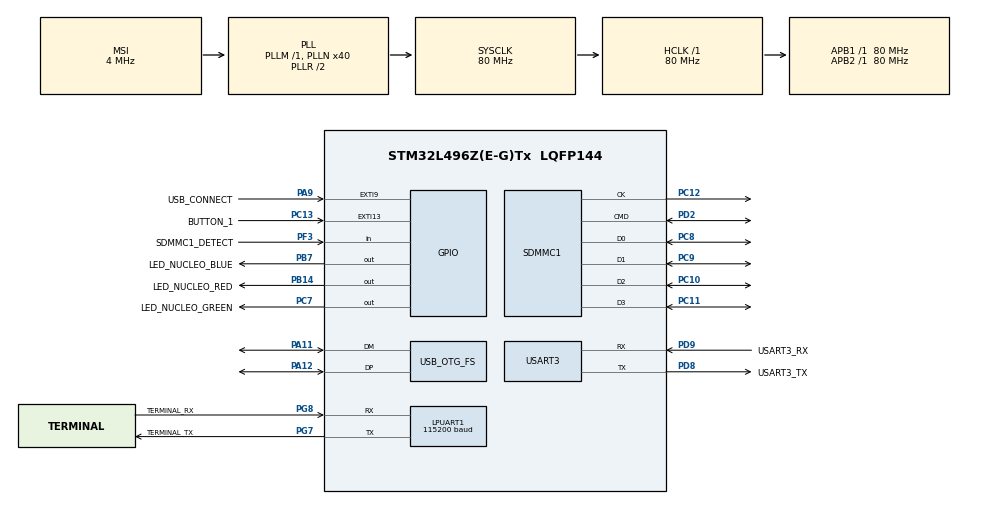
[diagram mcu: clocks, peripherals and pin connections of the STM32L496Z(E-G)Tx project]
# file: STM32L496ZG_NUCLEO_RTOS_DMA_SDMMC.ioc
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Dma.LPUART_RX.1.Direction=DMA_PERIPH_TO_MEMORY
Dma.LPUART_RX.1.Instance=DMA2_Channel7
Dma.LPUART_RX.1.MemDataAlignment=DMA_MDATAALIGN_BYTE
Dma.LPUART_RX.1.MemInc=DMA_MINC_ENABLE
Dma.LPUART_RX.1.Mode=DMA_CIRCULAR
Dma.LPUART_RX.1.PeriphDataAlignment=DMA_PDATAALIGN_BYTE
Dma.LPUART_RX.1.PeriphInc=DMA_PINC_DISABLE
Dma.LPUART_RX.1.Priority=DMA_PRIORITY_LOW
Dma.LPUART_TX.2.Direction=DMA_MEMORY_TO_PERIPH
Dma.LPUART_TX.2.Instance=DMA2_Channel6
Dma.LPUART_TX.2.MemDataAlignment=DMA_MDATAALIGN_BYTE
Dma.LPUART_TX.2.MemInc=DMA_MINC_ENABLE
Dma.LPUART_TX.2.Mode=DMA_NORMAL
Dma.LPUART_TX.2.PeriphDataAlignment=DMA_PDATAALIGN_BYTE
Dma.LPUART_TX.2.PeriphInc=DMA_PINC_DISABLE
Dma.LPUART_TX.2.Priority=DMA_PRIORITY_LOW
Dma.Request0=SDMMC1
Dma.Request1=LPUART_RX
Dma.Request2=LPUART_TX
Dma.Request3=USART3_RX
Dma.Request4=USART3_TX
Dma.SDMMC1.0.Direction=DMA_PERIPH_TO_MEMORY
Dma.SDMMC1.0.Instance=DMA2_Channel4
Dma.SDMMC1.0.MemDataAlignment=DMA_MDATAALIGN_WORD
Dma.SDMMC1.0.MemInc=DMA_MINC_ENABLE
Dma.SDMMC1.0.Mode=DMA_NORMAL
Dma.SDMMC1.0.PeriphDataAlignment=DMA_PDATAALIGN_WORD
Dma.SDMMC1.0.PeriphInc=DMA_PINC_DISABLE
Dma.SDMMC1.0.Priority=DMA_PRIORITY_LOW
Dma.USART3_RX.3.Direction=DMA_PERIPH_TO_MEMORY
Dma.USART3_RX.3.Instance=DMA1_Channel3
Dma.USART3_RX.3.MemDataAlignment=DMA_MDATAALIGN_BYTE
Dma.USART3_RX.3.MemInc=DMA_MINC_ENABLE
Dma.USART3_RX.3.Mode=DMA_NORMAL
Dma.USART3_RX.3.PeriphDataAlignment=DMA_PDATAALIGN_BYTE
Dma.USART3_RX.3.PeriphInc=DMA_PINC_DISABLE
Dma.USART3_RX.3.Priority=DMA_PRIORITY_LOW
Dma.USART3_TX.4.Direction=DMA_MEMORY_TO_PERIPH
Dma.USART3_TX.4.Instance=DMA1_Channel2
Dma.USART3_TX.4.MemDataAlignment=DMA_MDATAALIGN_BYTE
Dma.USART3_TX.4.MemInc=DMA_MINC_ENABLE
Dma.USART3_TX.4.Mode=DMA_NORMAL
Dma.USART3_TX.4.PeriphDataAlignment=DMA_PDATAALIGN_BYTE
Dma.USART3_TX.4.PeriphInc=DMA_PINC_DISABLE
Dma.USART3_TX.4.Priority=DMA_PRIORITY_LOW
FATFS.BSP.number=1
FATFS._USE_FIND=1
FATFS._USE_LFN=2
FATFS0.BSP.STBoard=false
FATFS0.BSP.api=Unknown
FATFS0.BSP.i2caddr=0
FATFS0.BSP.instance=PF3
FATFS0.BSP.ip=GPIO
FATFS0.BSP.mode=Input
FATFS0.BSP.name=Detect_SDIO
FATFS0.BSP.solution=PF3
FREERTOS.INCLUDE_uxTaskGetStackHighWaterMark=1
FREERTOS.Tasks01=defaultTask,0,1024,StartDefaultTask,Default,NULL,Dynamic,NULL,NULL
FREERTOS.configCHECK_FOR_STACK_OVERFLOW=2
FREERTOS.configENABLE_BACKWARD_COMPATIBILITY=0
FREERTOS.configGENERATE_RUN_TIME_STATS=1
FREERTOS.configRECORD_STACK_HIGH_ADDRESS=1
FREERTOS.configTOTAL_HEAP_SIZE=204800
FREERTOS.configUSE_IDLE_HOOK=1
FREERTOS.configUSE_STATS_FORMATTING_FUNCTIONS=1
FREERTOS.configUSE_TRACE_FACILITY=1
LPUART1.BaudRate=115200
LPUART1.WordLength=UART_WORDLENGTH_8B
Mcu.Family=STM32L4
Mcu.Name=STM32L496Z(E-G)Tx
Mcu.Package=LQFP144
NVIC.DMA1_Channel2_IRQn=true\:5\:0\:false\:false\:true\:true\:false\:true
NVIC.DMA1_Channel3_IRQn=true\:5\:0\:false\:false\:true\:true\:false\:true
NVIC.DMA2_Channel4_IRQn=true\:5\:0\:false\:false\:true\:true\:false\:true
NVIC.DMA2_Channel6_IRQn=true\:5\:0\:false\:false\:true\:true\:false\:true
NVIC.DMA2_Channel7_IRQn=true\:5\:0\:false\:false\:true\:true\:false\:true
NVIC.EXTI15_10_IRQn=true\:5\:0\:false\:false\:true\:true\:true\:true
NVIC.EXTI9_5_IRQn=true\:5\:0\:false\:false\:true\:true\:true\:true
NVIC.LPUART1_IRQn=true\:5\:0\:false\:false\:true\:true\:true\:true
NVIC.OTG_FS_IRQn=true\:5\:0\:false\:false\:true\:true\:false\:true
NVIC.PriorityGroup=NVIC_PRIORITYGROUP_4
NVIC.RTC_Alarm_IRQn=true\:5\:0\:false\:false\:true\:true\:true\:true
NVIC.SDMMC1_IRQn=true\:5\:0\:false\:false\:true\:true\:true\:true
NVIC.TIM2_IRQn=true\:0\:0\:false\:false\:true\:false\:false\:true
NVIC.TIM7_IRQn=true\:5\:0\:false\:false\:true\:true\:true\:true
NVIC.TimeBase=TIM2_IRQn
NVIC.TimeBaseIP=TIM2
NVIC.USART3_IRQn=true\:5\:0\:false\:false\:true\:true\:true\:true
PA11.Mode=Device_Only
PA11.Signal=USB_OTG_FS_DM
PA12.Mode=Device_Only
PA12.Signal=USB_OTG_FS_DP
PA13\ (JTMS/SWDIO).Mode=Trace_Asynchronous_SW
PA13\ (JTMS/SWDIO).Signal=SYS_JTMS-SWDIO
PA14\ (JTCK/SWCLK).Mode=Trace_Asynchronous_SW
PA14\ (JTCK/SWCLK).Signal=SYS_JTCK-SWCLK
PA9.GPIO_Label=USB_CONNECT
PA9.GPIO_ModeDefaultEXTI=GPIO_MODE_IT_RISING_FALLING
PA9.Signal=GPXTI9
PB14.GPIO_Label=LED_NUCLEO_RED
PB14.Signal=GPIO_Output
PB3\ (JTDO/TRACESWO).Mode=Trace_Asynchronous_SW
PB3\ (JTDO/TRACESWO).Signal=SYS_JTDO-SWO
PB7.GPIO_Label=LED_NUCLEO_BLUE
PB7.Signal=GPIO_Output
PC10.Mode=SD_4_bits_Wide_bus
PC10.Signal=SDMMC1_D2
PC11.Mode=SD_4_bits_Wide_bus
PC11.Signal=SDMMC1_D3
PC12.Mode=SD_4_bits_Wide_bus
PC12.Signal=SDMMC1_CK
PC13.GPIO_Label=BUTTON_1
PC13.GPIO_ModeDefaultEXTI=GPIO_MODE_IT_RISING
PC13.Signal=GPXTI13
PC7.GPIO_Label=LED_NUCLEO_GREEN
PC7.Signal=GPIO_Output
PC8.Mode=SD_4_bits_Wide_bus
PC8.Signal=SDMMC1_D0
PC9.Mode=SD_4_bits_Wide_bus
PC9.Signal=SDMMC1_D1
PD2.Mode=SD_4_bits_Wide_bus
PD2.Signal=SDMMC1_CMD
PD8.GPIO_Label=USART3_TX
PD8.Mode=Asynchronous
PD8.Signal=USART3_TX
PD9.GPIO_Label=USART3_RX
PD9.Mode=Asynchronous
PD9.Signal=USART3_RX
PF3.GPIO_Label=SDMMC1_DETECT
PF3.GPIO_PuPd=GPIO_PULLUP
PF3.Signal=GPIO_Input
PG7.GPIO_Label=TERMINAL_TX
PG7.Mode=Asynchronous
PG7.Signal=LPUART1_TX
PG8.GPIO_Label=TERMINAL_RX
PG8.Mode=Asynchronous
PG8.Signal=LPUART1_RX
ProjectManager.HeapSize=0x4000
ProjectManager.StackSize=0x8000
ProjectManager.TargetToolchain=STM32CubeIDE
RCC.ADCFreq_Value=48000000
RCC.AHBFreq_Value=80000000
RCC.APB1Freq_Value=80000000
RCC.APB1TimFreq_Value=80000000
RCC.APB2Freq_Value=80000000
RCC.APB2TimFreq_Value=80000000
RCC.CortexFreq_Value=80000000
RCC.HCLKFreq_Value=80000000
RCC.HSE_VALUE=8000000
RCC.HSI48_VALUE=48000000
RCC.HSI_VALUE=16000000
RCC.LSE_VALUE=32768
RCC.MSI_VALUE=4000000
RCC.PLLN=40
RCC.PLLSAI1N=24
RCC.SYSCLKFreq_VALUE=80000000
RCC.SYSCLKSource=RCC_SYSCLKSOURCE_PLLCLK
RCC.USBFreq_Value=48000000
RCC.VCOOutputFreq_Value=160000000
RTC.Alarm-Alarm\ A=RTC_ALARM_A
RTC.Date=6
RTC.Format=RTC_FORMAT_BIN
RTC.SynchPrediv=249
RTC.WeekDay=RTC_WEEKDAY_SUNDAY
RTC.Year=80
SDMMC1.ClockDiv=8
TIM1.Period=255
TIM1.Prescaler=1230
TIM7.Period=1
TIM7.Prescaler=1600
USART3.VirtualMode-Asynchronous=VM_ASYNC
USB_DEVICE.CLASS_NAME_FS=MSC
USB_DEVICE.MSC_MEDIA_PACKET=32768
USB_DEVICE.PRODUCT_STRING_MSC_FS=EOS Mass Storage
USB_DEVICE.VirtualMode=Msc
USB_DEVICE.VirtualModeFS=Msc_FS
USB_OTG_FS.VirtualMode=Device_Only
VP_FATFS_VS_SDIO.Mode=SDIO
VP_FREERTOS_VS_CMSIS_V1.Mode=CMSIS_V1
VP_RTC_VS_RTC_Activate.Mode=RTC_Enabled
VP_RTC_VS_RTC_Alarm_A_Intern.Mode=Alarm A
VP_RTC_VS_RTC_Calendar.Mode=RTC_Calendar
VP_SYS_VS_tim2.Mode=TIM2
VP_TIM1_VS_ClockSourceINT.Mode=Internal
VP_TIM7_VS_ClockSourceINT.Mode=Enable_Timer
VP_USB_DEVICE_VS_USB_DEVICE_MSC_FS.Mode=MSC_FS
board=custom

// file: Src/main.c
/* USER CODE BEGIN Header */
/**
  ******************************************************************************
  * @file           : main.c
  * @brief          : Main program body
  ******************************************************************************
  * @attention
  *
  * <h2><center>&copy; Copyright (c) 2023 STMicroelectronics.
  * All rights reserved.</center></h2>
  *
  * This software component is licensed by ST under Ultimate Liberty license
  * SLA0044, the "License"; You may not use this file except in compliance with
  * the License. You may obtain a copy of the License at:
  *                             www.st.com/SLA0044
  *
  ******************************************************************************
  */
/* USER CODE END Header */

#include "main.h"
#include "cmsis_os.h"
#include "dma.h"
#include "fatfs.h"
#include "usart.h"
#include "rtc.h"
#include "sdmmc.h"
#include "tim.h"
#include "usb_device.h"
#include "gpio.h"

void SystemClock_Config(void);
void MX_FREERTOS_Init(void);

/* USER CODE BEGIN 0 */
void ITM_Out(uint32_t port,uint32_t ch){
	while( ITM->PORT[port].u32 == 0);
		ITM->PORT[port].u8 = (uint8_t) ch;
}

// copy of _write function with addition of port selection
void swvPrint(int port, char* ptr, int len){
	int i = 0;
	for (i = 0; i < len; i++)
		ITM_Out(port, (uint32_t) *ptr++);
}

/* USER CODE END 0 */

int main(void)
{

  /* MCU Configuration--------------------------------------------------------*/

  /* Reset of all peripherals, Initializes the Flash interface and the Systick. */
  HAL_Init();

  /* Configure the system clock */
  SystemClock_Config();

  /* Initialize all configured peripherals */
  MX_GPIO_Init();
  MX_DMA_Init();
  MX_RTC_Init();
  MX_SDMMC1_SD_Init();
  MX_TIM7_Init();
  MX_USART3_UART_Init();
  MX_LPUART1_UART_Init();
  MX_TIM1_Init();
  /* USER CODE BEGIN 2 */

  SEGGER_SYSVIEW_Conf();
  /* USER CODE END 2 */

  /* Call init function for freertos objects (in freertos.c) */
  MX_FREERTOS_Init();

  /* Start scheduler */
  osKernelStart();

  /* We should never get here as control is now taken by the scheduler */

  /* Infinite loop */
  while (1)
  {

  }
}

void SystemClock_Config(void)
{
  RCC_OscInitTypeDef RCC_OscInitStruct = {0};
  RCC_ClkInitTypeDef RCC_ClkInitStruct = {0};
  RCC_PeriphCLKInitTypeDef PeriphClkInit = {0};

  /** Initializes the CPU, AHB and APB busses clocks
  */
  RCC_OscInitStruct.OscillatorType = RCC_OSCILLATORTYPE_LSI|RCC_OSCILLATORTYPE_LSE
                              |RCC_OSCILLATORTYPE_MSI;
  RCC_OscInitStruct.LSEState = RCC_LSE_OFF;
  RCC_OscInitStruct.LSIState = RCC_LSI_ON;
  RCC_OscInitStruct.MSIState = RCC_MSI_ON;
  RCC_OscInitStruct.MSICalibrationValue = 0;
  RCC_OscInitStruct.MSIClockRange = RCC_MSIRANGE_6;
  RCC_OscInitStruct.PLL.PLLState = RCC_PLL_ON;
  RCC_OscInitStruct.PLL.PLLSource = RCC_PLLSOURCE_MSI;
  RCC_OscInitStruct.PLL.PLLM = 1;
  RCC_OscInitStruct.PLL.PLLN = 40;
  RCC_OscInitStruct.PLL.PLLP = RCC_PLLP_DIV2;
  RCC_OscInitStruct.PLL.PLLQ = RCC_PLLQ_DIV2;
  RCC_OscInitStruct.PLL.PLLR = RCC_PLLR_DIV2;
  if (HAL_RCC_OscConfig(&RCC_OscInitStruct) != HAL_OK)
  {
    Error_Handler();
  }
  /** Initializes the CPU, AHB and APB busses clocks
  */
  RCC_ClkInitStruct.ClockType = RCC_CLOCKTYPE_HCLK|RCC_CLOCKTYPE_SYSCLK
                              |RCC_CLOCKTYPE_PCLK1|RCC_CLOCKTYPE_PCLK2;
  RCC_ClkInitStruct.SYSCLKSource = RCC_SYSCLKSOURCE_PLLCLK;
  RCC_ClkInitStruct.AHBCLKDivider = RCC_SYSCLK_DIV1;
  RCC_ClkInitStruct.APB1CLKDivider = RCC_HCLK_DIV1;
  RCC_ClkInitStruct.APB2CLKDivider = RCC_HCLK_DIV1;

  if (HAL_RCC_ClockConfig(&RCC_ClkInitStruct, FLASH_LATENCY_4) != HAL_OK)
  {
    Error_Handler();
  }
  PeriphClkInit.PeriphClockSelection = RCC_PERIPHCLK_RTC|RCC_PERIPHCLK_USART3
                              |RCC_PERIPHCLK_LPUART1|RCC_PERIPHCLK_USB
                              |RCC_PERIPHCLK_SDMMC1;
  PeriphClkInit.Usart3ClockSelection = RCC_USART3CLKSOURCE_PCLK1;
  PeriphClkInit.Lpuart1ClockSelection = RCC_LPUART1CLKSOURCE_PCLK1;
  PeriphClkInit.RTCClockSelection = RCC_RTCCLKSOURCE_LSI;
  PeriphClkInit.UsbClockSelection = RCC_USBCLKSOURCE_PLLSAI1;
  PeriphClkInit.Sdmmc1ClockSelection = RCC_SDMMC1CLKSOURCE_PLLSAI1;
  PeriphClkInit.PLLSAI1.PLLSAI1Source = RCC_PLLSOURCE_MSI;
  PeriphClkInit.PLLSAI1.PLLSAI1M = 1;
  PeriphClkInit.PLLSAI1.PLLSAI1N = 24;
  PeriphClkInit.PLLSAI1.PLLSAI1P = RCC_PLLP_DIV2;
  PeriphClkInit.PLLSAI1.PLLSAI1Q = RCC_PLLQ_DIV2;
  PeriphClkInit.PLLSAI1.PLLSAI1R = RCC_PLLR_DIV2;
  PeriphClkInit.PLLSAI1.PLLSAI1ClockOut = RCC_PLLSAI1_48M2CLK;
  if (HAL_RCCEx_PeriphCLKConfig(&PeriphClkInit) != HAL_OK)
  {
    Error_Handler();
  }
  /** Configure the main internal regulator output voltage
  */
  if (HAL_PWREx_ControlVoltageScaling(PWR_REGULATOR_VOLTAGE_SCALE1) != HAL_OK)
  {
    Error_Handler();
  }
  /** Enable MSI Auto calibration
  */
  HAL_RCCEx_EnableMSIPLLMode();
}

void HAL_TIM_PeriodElapsedCallback(TIM_HandleTypeDef *htim)
{
  if (htim->Instance == TIM2) {
    HAL_IncTick();
  }
}

void Error_Handler(void)
{
}

/************************ (C) COPYRIGHT STMicroelectronics *****END OF FILE****/

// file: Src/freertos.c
/* USER CODE BEGIN Header */
/**
  ******************************************************************************
  * File Name          : freertos.c
  * Description        : Code for freertos applications
  ******************************************************************************
  * @attention
  *
  * <h2><center>&copy; Copyright (c) 2023 STMicroelectronics.
  * All rights reserved.</center></h2>
  *
  * This software component is licensed by ST under Ultimate Liberty license
  * SLA0044, the "License"; You may not use this file except in compliance with
  * the License. You may obtain a copy of the License at:
  *                             www.st.com/SLA0044
  *
  ******************************************************************************
  */
/* USER CODE END Header */

#include "FreeRTOS.h"
#include "task.h"
#include "main.h"
#include "cmsis_os.h"

/* USER CODE BEGIN Includes */
#include "mainApp.h"
/* USER CODE END Includes */

osThreadId defaultTaskHandle;

void StartDefaultTask(void const * argument);

void MX_FREERTOS_Init(void); /* (MISRA C 2004 rule 8.1) */

/* Hook prototypes */
void configureTimerForRunTimeStats(void);
unsigned long getRunTimeCounterValue(void);
void vApplicationIdleHook(void);
void vApplicationStackOverflowHook(TaskHandle_t xTask, signed char *pcTaskName);

/* USER CODE BEGIN 1 */
/* Functions needed when configGENERATE_RUN_TIME_STATS is on */
__weak void configureTimerForRunTimeStats(void)
{

}

__weak unsigned long getRunTimeCounterValue(void)
{
return 0;
}
/* USER CODE END 1 */

/* USER CODE BEGIN 2 */
__weak void vApplicationIdleHook( void )
{
   /* vApplicationIdleHook() will only be called if configUSE_IDLE_HOOK is set
   to 1 in FreeRTOSConfig.h. It will be called on each iteration of the idle
   task. It is essential that code added to this hook function never attempts
   to block in any way (for example, call xQueueReceive() with a block time
   specified, or call vTaskDelay()). If the application makes use of the
   vTaskDelete() API function (as this demo application does) then it is also
   important that vApplicationIdleHook() is permitted to return to its calling
   function, because it is the responsibility of the idle task to clean up
   memory allocated by the kernel to any task that has since been deleted. */
}
/* USER CODE END 2 */

/* USER CODE BEGIN 4 */
__weak void vApplicationStackOverflowHook(TaskHandle_t xTask, signed char *pcTaskName)
{
   /* Run time stack overflow checking is performed if
   configCHECK_FOR_STACK_OVERFLOW is defined to 1 or 2. This hook function is
   called if a stack overflow is detected. */
}
/* USER CODE END 4 */

void MX_FREERTOS_Init(void) {

  /* Create the thread(s) */
  /* definition and creation of defaultTask */
  osThreadDef(defaultTask, StartDefaultTask, osPriorityNormal, 0, 1024);
  defaultTaskHandle = osThreadCreate(osThread(defaultTask), NULL);

}

void StartDefaultTask(void const * argument)
{

  /* USER CODE BEGIN StartDefaultTask */

  // Start main app
  mainApp_start();

  // Delete task
  vTaskDelete( NULL );
  /* USER CODE END StartDefaultTask */
}

/************************ (C) COPYRIGHT STMicroelectronics *****END OF FILE****/
